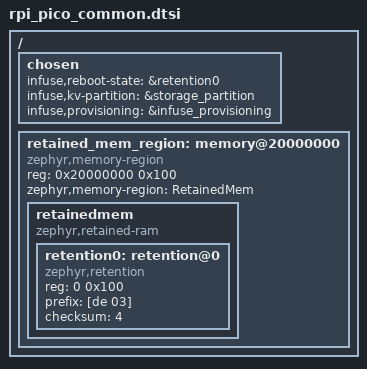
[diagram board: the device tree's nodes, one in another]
/*
 * Copyright (c) 2026 Embeint Holdings Pty Ltd
 * SPDX-License-Identifier: FSL-1.1-ALv2
 */

/ {
	chosen {
		infuse,reboot-state = &retention0;
		infuse,kv-partition = &storage_partition;
		infuse,provisioning = &infuse_provisioning;
	};

	/* Keep reboot state at the start of SRAM, away from boot ROM scratch RAM. */
	retained_mem_region: memory@20000000 {
		compatible = "zephyr,memory-region", "mmio-sram";
		reg = <0x20000000 0x100>;
		zephyr,memory-region = "RetainedMem";

		retainedmem {
			compatible = "zephyr,retained-ram";
			#address-cells = <1>;
			#size-cells = <1>;

			retention0: retention@0 {
				compatible = "zephyr,retention";
				reg = <0 0x100>;
				prefix = [de 03];
				checksum = <4>;
			};
		};
	};
};
